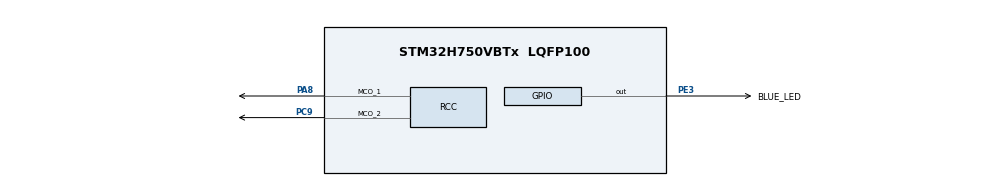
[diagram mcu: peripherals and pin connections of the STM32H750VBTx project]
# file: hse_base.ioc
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CORTEX_M7.CPU_DCache=Enabled
CORTEX_M7.CPU_ICache=Enabled
CORTEX_M7.MPU_Control=__NULL
CORTEX_M7.default_mode_Activation=0
Mcu.Family=STM32H7
Mcu.Name=STM32H750VBTx
Mcu.Package=LQFP100
NVIC.PriorityGroup=NVIC_PRIORITYGROUP_4
PA13\ (JTMS/SWDIO).Mode=Serial_Wire
PA13\ (JTMS/SWDIO).Signal=DEBUG_JTMS-SWDIO
PA14\ (JTCK/SWCLK).Mode=Serial_Wire
PA14\ (JTCK/SWCLK).Signal=DEBUG_JTCK-SWCLK
PA8.GPIO_Speed=GPIO_SPEED_FREQ_VERY_HIGH
PA8.Mode=Clock-out-1
PA8.Signal=RCC_MCO_1
PC7.Mode=External_Trigger_bidirectional
PC7.Signal=DEBUG_TRGIO
PC9.GPIO_Speed=GPIO_SPEED_FREQ_VERY_HIGH
PC9.Mode=Clock-out-2
PC9.Signal=RCC_MCO_2
PE3.GPIO_Label=BLUE_LED
PE3.Signal=GPIO_Output
PH0-OSC_IN\ (PH0).Mode=HSE-External-Oscillator
PH0-OSC_IN\ (PH0).Signal=RCC_OSC_IN
PH1-OSC_OUT\ (PH1).Mode=HSE-External-Oscillator
PH1-OSC_OUT\ (PH1).Signal=RCC_OSC_OUT
ProjectManager.HeapSize=0x200
ProjectManager.StackSize=0x400
ProjectManager.TargetToolchain=STM32CubeIDE
RCC.ADCFreq_Value=50390625
RCC.APB1Freq_Value=120000000
RCC.APB2Freq_Value=120000000
RCC.APB3Freq_Value=120000000
RCC.APB4Freq_Value=120000000
RCC.CortexFreq_Value=480000000
RCC.D1PPRE=RCC_APB3_DIV2
RCC.D2PPRE1=RCC_APB1_DIV2
RCC.D2PPRE2=RCC_APB2_DIV2
RCC.D3PPRE=RCC_APB4_DIV2
RCC.DIVM1=5
RCC.DIVN1=192
RCC.HCLKFreq_Value=240000000
RCC.HPRE=RCC_HCLK_DIV2
RCC.HSE_Timout=1000
RCC.HSE_VALUE=25000000
RCC.PLL2FRACN=0
RCC.PLL3FRACN=0
RCC.PLLFRACN=0
RCC.PLLSourceVirtual=RCC_PLLSOURCE_HSE
RCC.RCC_MCO1Source=RCC_MCO1SOURCE_PLL1QCLK
RCC.RCC_MCO2Source=RCC_MCO2SOURCE_HSE
RCC.SYSCLKFreq_VALUE=480000000
RCC.SYSCLKSource=RCC_SYSCLKSOURCE_PLLCLK
RCC.USBFreq_Value=480000000
board=custom

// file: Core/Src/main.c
/* USER CODE BEGIN Header */
/**
  ******************************************************************************
  * @file           : main.c
  * @brief          : Main program body
  ******************************************************************************
  * @attention
  *
  * Copyright (c) 2026 STMicroelectronics.
  * All rights reserved.
  *
  * This software is licensed under terms that can be found in the LICENSE file
  * in the root directory of this software component.
  * If no LICENSE file comes with this software, it is provided AS-IS.
  *
  ******************************************************************************
  */
/* USER CODE END Header */
#include "main.h"

/* USER CODE BEGIN PV */
static volatile uint32_t delayCounter = 0;
/* USER CODE END PV */

void SystemClock_Config(void);
static void MX_GPIO_Init(void);

int main(void)
{

  /* Enable the CPU Cache */

  /* Enable I-Cache---------------------------------------------------------*/
  SCB_EnableICache();

  /* Enable D-Cache---------------------------------------------------------*/
  SCB_EnableDCache();

  /* MCU Configuration--------------------------------------------------------*/

  /* Reset of all peripherals, Initializes the Flash interface and the Systick. */
  HAL_Init();

  /* Configure the system clock */
  SystemClock_Config();

  /* Initialize all configured peripherals */
  MX_GPIO_Init();

  /* Infinite loop */
  while (1)
  {

    /* USER CODE BEGIN 3 */
	HAL_GPIO_TogglePin(BLUE_LED_GPIO_Port, BLUE_LED_Pin);

	delayCounter = 50000000; // 50_000_000

	for (; delayCounter > 0; delayCounter--);

  }
  /* USER CODE END 3 */
}

void SystemClock_Config(void)
{
  RCC_OscInitTypeDef RCC_OscInitStruct = {0};
  RCC_ClkInitTypeDef RCC_ClkInitStruct = {0};

  /** Supply configuration update enable
  */
  HAL_PWREx_ConfigSupply(PWR_LDO_SUPPLY);

  /** Configure the main internal regulator output voltage
  */
  __HAL_PWR_VOLTAGESCALING_CONFIG(PWR_REGULATOR_VOLTAGE_SCALE0);

  while(!__HAL_PWR_GET_FLAG(PWR_FLAG_VOSRDY)) {}

  /** Initializes the RCC Oscillators according to the specified parameters
  * in the RCC_OscInitTypeDef structure.
  */
  RCC_OscInitStruct.OscillatorType = RCC_OSCILLATORTYPE_HSE;
  RCC_OscInitStruct.HSEState = RCC_HSE_ON;
  RCC_OscInitStruct.PLL.PLLState = RCC_PLL_ON;
  RCC_OscInitStruct.PLL.PLLSource = RCC_PLLSOURCE_HSE;
  RCC_OscInitStruct.PLL.PLLM = 5;
  RCC_OscInitStruct.PLL.PLLN = 192;
  RCC_OscInitStruct.PLL.PLLP = 2;
  RCC_OscInitStruct.PLL.PLLQ = 2;
  RCC_OscInitStruct.PLL.PLLR = 2;
  RCC_OscInitStruct.PLL.PLLRGE = RCC_PLL1VCIRANGE_2;
  RCC_OscInitStruct.PLL.PLLVCOSEL = RCC_PLL1VCOWIDE;
  RCC_OscInitStruct.PLL.PLLFRACN = 0;
  if (HAL_RCC_OscConfig(&RCC_OscInitStruct) != HAL_OK)
  {
    Error_Handler();
  }

  /** Initializes the CPU, AHB and APB buses clocks
  */
  RCC_ClkInitStruct.ClockType = RCC_CLOCKTYPE_HCLK|RCC_CLOCKTYPE_SYSCLK
                              |RCC_CLOCKTYPE_PCLK1|RCC_CLOCKTYPE_PCLK2
                              |RCC_CLOCKTYPE_D3PCLK1|RCC_CLOCKTYPE_D1PCLK1;
  RCC_ClkInitStruct.SYSCLKSource = RCC_SYSCLKSOURCE_PLLCLK;
  RCC_ClkInitStruct.SYSCLKDivider = RCC_SYSCLK_DIV1;
  RCC_ClkInitStruct.AHBCLKDivider = RCC_HCLK_DIV2;
  RCC_ClkInitStruct.APB3CLKDivider = RCC_APB3_DIV2;
  RCC_ClkInitStruct.APB1CLKDivider = RCC_APB1_DIV2;
  RCC_ClkInitStruct.APB2CLKDivider = RCC_APB2_DIV2;
  RCC_ClkInitStruct.APB4CLKDivider = RCC_APB4_DIV2;

  if (HAL_RCC_ClockConfig(&RCC_ClkInitStruct, FLASH_LATENCY_4) != HAL_OK)
  {
    Error_Handler();
  }
  __HAL_RCC_PLLCLKOUT_ENABLE(RCC_PLL1_DIVQ);
  HAL_RCC_MCOConfig(RCC_MCO1, RCC_MCO1SOURCE_PLL1QCLK, RCC_MCODIV_1);
  HAL_RCC_MCOConfig(RCC_MCO2, RCC_MCO2SOURCE_HSE, RCC_MCODIV_1);
}

static void MX_GPIO_Init(void)
{
  GPIO_InitTypeDef GPIO_InitStruct = {0};

  /* GPIO Ports Clock Enable */
  __HAL_RCC_GPIOE_CLK_ENABLE();
  __HAL_RCC_GPIOH_CLK_ENABLE();
  __HAL_RCC_GPIOC_CLK_ENABLE();
  __HAL_RCC_GPIOA_CLK_ENABLE();

  /*Configure GPIO pin Output Level */
  HAL_GPIO_WritePin(BLUE_LED_GPIO_Port, BLUE_LED_Pin, GPIO_PIN_RESET);

  /*Configure GPIO pin : BLUE_LED_Pin */
  GPIO_InitStruct.Pin = BLUE_LED_Pin;
  GPIO_InitStruct.Mode = GPIO_MODE_OUTPUT_PP;
  GPIO_InitStruct.Pull = GPIO_NOPULL;
  GPIO_InitStruct.Speed = GPIO_SPEED_FREQ_LOW;
  HAL_GPIO_Init(BLUE_LED_GPIO_Port, &GPIO_InitStruct);

  /*Configure GPIO pin : PC9 */
  GPIO_InitStruct.Pin = GPIO_PIN_9;
  GPIO_InitStruct.Mode = GPIO_MODE_AF_PP;
  GPIO_InitStruct.Pull = GPIO_NOPULL;
  GPIO_InitStruct.Speed = GPIO_SPEED_FREQ_VERY_HIGH;
  GPIO_InitStruct.Alternate = GPIO_AF0_MCO;
  HAL_GPIO_Init(GPIOC, &GPIO_InitStruct);

  /*Configure GPIO pin : PA8 */
  GPIO_InitStruct.Pin = GPIO_PIN_8;
  GPIO_InitStruct.Mode = GPIO_MODE_AF_PP;
  GPIO_InitStruct.Pull = GPIO_NOPULL;
  GPIO_InitStruct.Speed = GPIO_SPEED_FREQ_VERY_HIGH;
  GPIO_InitStruct.Alternate = GPIO_AF0_MCO;
  HAL_GPIO_Init(GPIOA, &GPIO_InitStruct);

}

void Error_Handler(void)
{
  __disable_irq();
  while (1)
  {
  }
}
